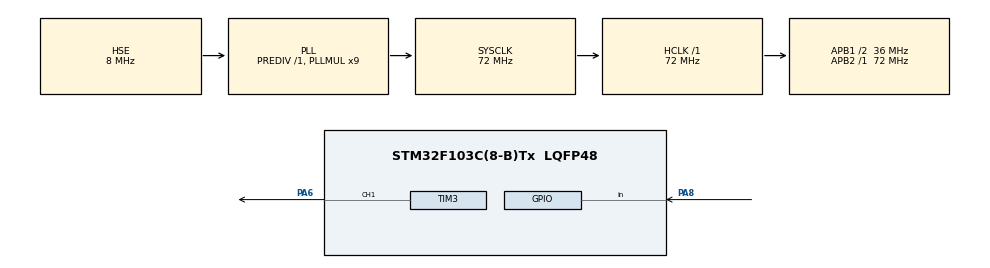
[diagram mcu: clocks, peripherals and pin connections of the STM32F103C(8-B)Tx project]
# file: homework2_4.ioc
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Mcu.Family=STM32F1
Mcu.Name=STM32F103C(8-B)Tx
Mcu.Package=LQFP48
NVIC.PriorityGroup=NVIC_PRIORITYGROUP_4
NVIC.TIM3_IRQn=true\:0\:0\:false\:false\:true\:true\:true\:true
NVIC.TIM4_IRQn=true\:0\:0\:false\:false\:true\:true\:true\:true
PA13.Mode=Serial_Wire
PA13.Signal=SYS_JTMS-SWDIO
PA14.Mode=Serial_Wire
PA14.Signal=SYS_JTCK-SWCLK
PA6.Signal=S_TIM3_CH1
PA8.GPIO_PuPd=GPIO_PULLUP
PA8.Signal=GPIO_Input
PD0-OSC_IN.Mode=HSE-External-Oscillator
PD0-OSC_IN.Signal=RCC_OSC_IN
PD1-OSC_OUT.Mode=HSE-External-Oscillator
PD1-OSC_OUT.Signal=RCC_OSC_OUT
ProjectManager.HeapSize=0x200
ProjectManager.StackSize=0x400
ProjectManager.TargetToolchain=MDK-ARM V5.32
RCC.AHBFreq_Value=72000000
RCC.APB1CLKDivider=RCC_HCLK_DIV2
RCC.APB1Freq_Value=36000000
RCC.APB1TimFreq_Value=72000000
RCC.APB2Freq_Value=72000000
RCC.APB2TimFreq_Value=72000000
RCC.HCLKFreq_Value=72000000
RCC.PLLMUL=RCC_PLL_MUL9
RCC.PLLSourceVirtual=RCC_PLLSOURCE_HSE
RCC.SYSCLKFreq_VALUE=72000000
RCC.SYSCLKSource=RCC_SYSCLKSOURCE_PLLCLK
RCC.USBFreq_Value=72000000
SH.S_TIM3_CH1.0=TIM3_CH1,PWM Generation1 CH1
TIM3.Channel-PWM\ Generation1\ CH1=TIM_CHANNEL_1
TIM3.OCPolarity_1=TIM_OCPOLARITY_LOW
TIM3.Period=1999
TIM3.Prescaler=71
TIM4.Period=999
TIM4.Prescaler=71
VP_TIM3_VS_ClockSourceINT.Mode=Internal
VP_TIM4_VS_ClockSourceINT.Mode=Internal
board=custom

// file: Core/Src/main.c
/* USER CODE BEGIN Header */
/**
  ******************************************************************************
  * @file           : main.c
  * @brief          : Main program body
  ******************************************************************************
  * @attention
  *
  * Copyright (c) 2026 STMicroelectronics.
  * All rights reserved.
  *
  * This software is licensed under terms that can be found in the LICENSE file
  * in the root directory of this software component.
  * If no LICENSE file comes with this software, it is provided AS-IS.
  *
  ******************************************************************************
  */
/* USER CODE END Header */
#include "main.h"

TIM_HandleTypeDef htim3;
TIM_HandleTypeDef htim4;

void SystemClock_Config(void);
static void MX_GPIO_Init(void);
static void MX_TIM3_Init(void);
static void MX_TIM4_Init(void);

/* USER CODE BEGIN 0 */
uint32_t temp,templast,num,sent;
uint32_t i,flag;
typedef enum{
	e_no=0,
	e_longpress,
	e_shortpress

} event;
volatile event ev;
typedef enum{
	s_25=0,
	s_50,
	s_75,
	s_100,
	s_PWM

} state;
state st,out;
/* USER CODE END 0 */

int main(void)
{

  /* MCU Configuration--------------------------------------------------------*/

  /* Reset of all peripherals, Initializes the Flash interface and the Systick. */
  HAL_Init();

  /* Configure the system clock */
  SystemClock_Config();

  /* Initialize all configured peripherals */
  MX_GPIO_Init();
  MX_TIM3_Init();
  MX_TIM4_Init();
  /* USER CODE BEGIN 2 */
  HAL_TIM_Base_Start_IT(&htim3);
  HAL_TIM_Base_Start_IT(&htim4);
  HAL_TIM_PWM_Start(&htim3,TIM_CHANNEL_1);
	 __HAL_TIM_SetCompare(&htim3,TIM_CHANNEL_1,500);

  /* USER CODE END 2 */

  /* Infinite loop */
  while (1)
  {

    /* USER CODE BEGIN 3 */
	 if(ev==0) continue;
	  switch(ev)
	  {
		  case(e_longpress):
		  {
		  if(st==s_PWM)
		  {
			  st=out;

		  }
			else
				{
					out=st;
					st=s_PWM;
				}
		   break;
		  }
		  case(e_shortpress):
		  {
			if(st==s_PWM) break;
			if(st==s_100) st=0;
			else st++;
			 break;
		  }
	  }
	  if(st!=s_PWM)
	 __HAL_TIM_SetCompare(&htim3,TIM_CHANNEL_1,(1+st)*500);
	  ev=0;

  }
  /* USER CODE END 3 */
}

void SystemClock_Config(void)
{
  RCC_OscInitTypeDef RCC_OscInitStruct = {0};
  RCC_ClkInitTypeDef RCC_ClkInitStruct = {0};

  /** Initializes the RCC Oscillators according to the specified parameters
  * in the RCC_OscInitTypeDef structure.
  */
  RCC_OscInitStruct.OscillatorType = RCC_OSCILLATORTYPE_HSE;
  RCC_OscInitStruct.HSEState = RCC_HSE_ON;
  RCC_OscInitStruct.HSEPredivValue = RCC_HSE_PREDIV_DIV1;
  RCC_OscInitStruct.HSIState = RCC_HSI_ON;
  RCC_OscInitStruct.PLL.PLLState = RCC_PLL_ON;
  RCC_OscInitStruct.PLL.PLLSource = RCC_PLLSOURCE_HSE;
  RCC_OscInitStruct.PLL.PLLMUL = RCC_PLL_MUL9;
  if (HAL_RCC_OscConfig(&RCC_OscInitStruct) != HAL_OK)
  {
    Error_Handler();
  }

  /** Initializes the CPU, AHB and APB buses clocks
  */
  RCC_ClkInitStruct.ClockType = RCC_CLOCKTYPE_HCLK|RCC_CLOCKTYPE_SYSCLK
                              |RCC_CLOCKTYPE_PCLK1|RCC_CLOCKTYPE_PCLK2;
  RCC_ClkInitStruct.SYSCLKSource = RCC_SYSCLKSOURCE_PLLCLK;
  RCC_ClkInitStruct.AHBCLKDivider = RCC_SYSCLK_DIV1;
  RCC_ClkInitStruct.APB1CLKDivider = RCC_HCLK_DIV2;
  RCC_ClkInitStruct.APB2CLKDivider = RCC_HCLK_DIV1;

  if (HAL_RCC_ClockConfig(&RCC_ClkInitStruct, FLASH_LATENCY_2) != HAL_OK)
  {
    Error_Handler();
  }
}

static void MX_TIM3_Init(void)
{

  TIM_ClockConfigTypeDef sClockSourceConfig = {0};
  TIM_MasterConfigTypeDef sMasterConfig = {0};
  TIM_OC_InitTypeDef sConfigOC = {0};

  htim3.Instance = TIM3;
  htim3.Init.Prescaler = 71;
  htim3.Init.CounterMode = TIM_COUNTERMODE_UP;
  htim3.Init.Period = 1999;
  htim3.Init.ClockDivision = TIM_CLOCKDIVISION_DIV1;
  htim3.Init.AutoReloadPreload = TIM_AUTORELOAD_PRELOAD_DISABLE;
  if (HAL_TIM_Base_Init(&htim3) != HAL_OK)
  {
    Error_Handler();
  }
  sClockSourceConfig.ClockSource = TIM_CLOCKSOURCE_INTERNAL;
  if (HAL_TIM_ConfigClockSource(&htim3, &sClockSourceConfig) != HAL_OK)
  {
    Error_Handler();
  }
  if (HAL_TIM_PWM_Init(&htim3) != HAL_OK)
  {
    Error_Handler();
  }
  sMasterConfig.MasterOutputTrigger = TIM_TRGO_RESET;
  sMasterConfig.MasterSlaveMode = TIM_MASTERSLAVEMODE_DISABLE;
  if (HAL_TIMEx_MasterConfigSynchronization(&htim3, &sMasterConfig) != HAL_OK)
  {
    Error_Handler();
  }
  sConfigOC.OCMode = TIM_OCMODE_PWM1;
  sConfigOC.Pulse = 0;
  sConfigOC.OCPolarity = TIM_OCPOLARITY_LOW;
  sConfigOC.OCFastMode = TIM_OCFAST_DISABLE;
  if (HAL_TIM_PWM_ConfigChannel(&htim3, &sConfigOC, TIM_CHANNEL_1) != HAL_OK)
  {
    Error_Handler();
  }
  HAL_TIM_MspPostInit(&htim3);

}

static void MX_TIM4_Init(void)
{

  TIM_ClockConfigTypeDef sClockSourceConfig = {0};
  TIM_MasterConfigTypeDef sMasterConfig = {0};

  htim4.Instance = TIM4;
  htim4.Init.Prescaler = 71;
  htim4.Init.CounterMode = TIM_COUNTERMODE_UP;
  htim4.Init.Period = 999;
  htim4.Init.ClockDivision = TIM_CLOCKDIVISION_DIV1;
  htim4.Init.AutoReloadPreload = TIM_AUTORELOAD_PRELOAD_DISABLE;
  if (HAL_TIM_Base_Init(&htim4) != HAL_OK)
  {
    Error_Handler();
  }
  sClockSourceConfig.ClockSource = TIM_CLOCKSOURCE_INTERNAL;
  if (HAL_TIM_ConfigClockSource(&htim4, &sClockSourceConfig) != HAL_OK)
  {
    Error_Handler();
  }
  sMasterConfig.MasterOutputTrigger = TIM_TRGO_RESET;
  sMasterConfig.MasterSlaveMode = TIM_MASTERSLAVEMODE_DISABLE;
  if (HAL_TIMEx_MasterConfigSynchronization(&htim4, &sMasterConfig) != HAL_OK)
  {
    Error_Handler();
  }

}

static void MX_GPIO_Init(void)
{
  GPIO_InitTypeDef GPIO_InitStruct = {0};

  /* GPIO Ports Clock Enable */
  __HAL_RCC_GPIOD_CLK_ENABLE();
  __HAL_RCC_GPIOA_CLK_ENABLE();

  /*Configure GPIO pin : PA8 */
  GPIO_InitStruct.Pin = GPIO_PIN_8;
  GPIO_InitStruct.Mode = GPIO_MODE_INPUT;
  GPIO_InitStruct.Pull = GPIO_PULLUP;
  HAL_GPIO_Init(GPIOA, &GPIO_InitStruct);

}

/* USER CODE BEGIN 4 */
void HAL_TIM_PeriodElapsedCallback(TIM_HandleTypeDef *htim)
{
	if(htim->Instance==TIM4)
	{
		temp=HAL_GPIO_ReadPin(GPIOA,GPIO_PIN_8);
	if(temp==templast) num++;
		else
		{
			if(num>=20)
			{
				if(num>=1000)
				{
					if(temp==1)
					{
						ev=e_longpress;
					}
				}
				else
				{
					if(temp==1)
					{
						ev=e_shortpress;
					}
				}

			}
			templast = temp;
			num=0;
		}

	}
	if(htim->Instance==TIM3)
	{
		if(st==s_PWM)
		{
			if(flag==0)
			{
				i+=4;
				if(i==2000) flag=1;
			}
			else if(flag==1)
			{
			i-=4;
				if(i==0) flag=0;

			}
			__HAL_TIM_SetCompare(&htim3,TIM_CHANNEL_1,i);
		}
	}

}

/* USER CODE END 4 */

void Error_Handler(void)
{
  __disable_irq();
  while (1)
  {
  }
}
